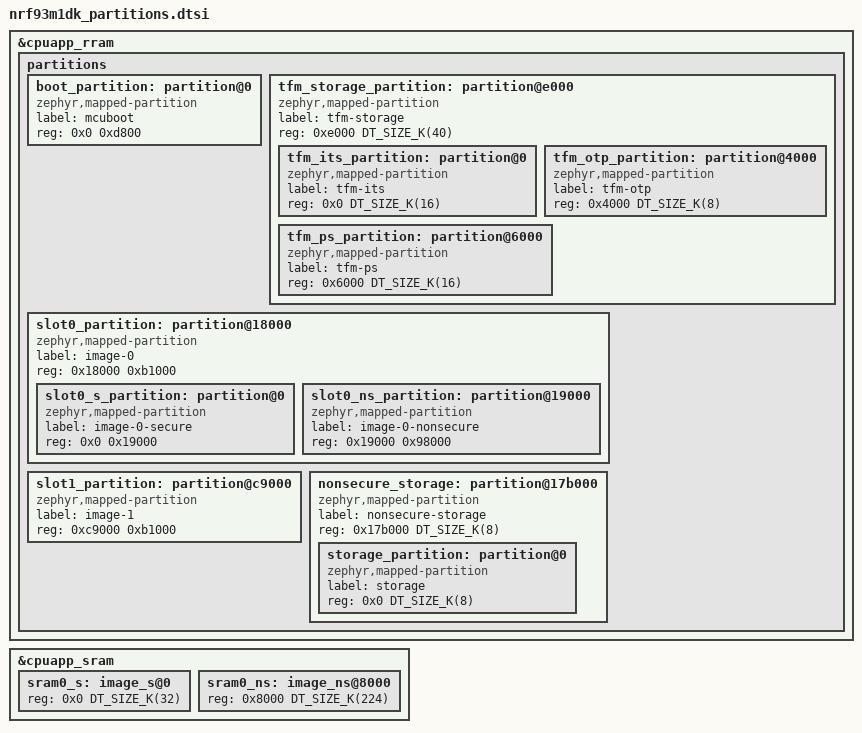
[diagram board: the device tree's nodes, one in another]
/*
 * Copyright (c) 2026 Nordic Semiconductor ASA
 *
 * SPDX-License-Identifier: LicenseRef-Nordic-5-Clause
 */

/* Drop the board-default (no-MCUboot) partition and SRAM nodes. */
/delete-node/ &slot0_partition;
/delete-node/ &slot0_ns_partition;
/delete-node/ &tfm_ps_partition;
/delete-node/ &tfm_its_partition;
/delete-node/ &tfm_otp_partition;
/delete-node/ &storage_partition;
/delete-node/ &sram0_s;
/delete-node/ &sram0_ns;

&cpuapp_rram {
	partitions {
		boot_partition: partition@0 {
			compatible = "zephyr,mapped-partition";
			label = "mcuboot";
			reg = <0x0 0xd800>;
		};

		tfm_storage_partition: partition@e000 {
			compatible = "zephyr,mapped-partition";
			label = "tfm-storage";
			reg = <0xe000 DT_SIZE_K(40)>;
			ranges = <0x0 0xe000 DT_SIZE_K(40)>;
			#address-cells = <1>;
			#size-cells = <1>;

			tfm_its_partition: partition@0 {
				compatible = "zephyr,mapped-partition";
				label = "tfm-its";
				reg = <0x0 DT_SIZE_K(16)>;
			};

			tfm_otp_partition: partition@4000 {
				compatible = "zephyr,mapped-partition";
				label = "tfm-otp";
				reg = <0x4000 DT_SIZE_K(8)>;
			};

			tfm_ps_partition: partition@6000 {
				compatible = "zephyr,mapped-partition";
				label = "tfm-ps";
				reg = <0x6000 DT_SIZE_K(16)>;
			};
		};

		slot0_partition: partition@18000 {
			compatible = "zephyr,mapped-partition";
			label = "image-0";
			reg = <0x18000 0xb1000>;
			ranges = <0x0 0x18000 0xb1000>;
			#address-cells = <1>;
			#size-cells = <1>;

			slot0_s_partition: partition@0 {
				compatible = "zephyr,mapped-partition";
				label = "image-0-secure";
				reg = <0x0 0x19000>;
			};

			slot0_ns_partition: partition@19000 {
				compatible = "zephyr,mapped-partition";
				label = "image-0-nonsecure";
				reg = <0x19000 0x98000>;
			};
		};

		slot1_partition: partition@c9000 {
			compatible = "zephyr,mapped-partition";
			label = "image-1";
			reg = <0xc9000 0xb1000>;
		};

		nonsecure_storage: partition@17b000 {
			compatible = "zephyr,mapped-partition";
			label = "nonsecure-storage";
			reg = <0x17b000 DT_SIZE_K(8)>;
			ranges = <0x0 0x17b000 DT_SIZE_K(8)>;
			#address-cells = <1>;
			#size-cells = <1>;

			storage_partition: partition@0 {
				compatible = "zephyr,mapped-partition";
				label = "storage";
				reg = <0x0 DT_SIZE_K(8)>;
			};
		};
	};
};

/* SRAM: 32 KB secure / 224 KB non-secure */
&cpuapp_sram {
	sram0_s: image_s@0 {
		#address-cells = <1>;
		#size-cells = <1>;
		reg = <0x0 DT_SIZE_K(32)>;
		ranges = <0x0 0x0 DT_SIZE_K(32)>;
	};

	sram0_ns: image_ns@8000 {
		#address-cells = <1>;
		#size-cells = <1>;
		reg = <0x8000 DT_SIZE_K(224)>;
		ranges = <0x0 0x8000 DT_SIZE_K(224)>;
	};
};
